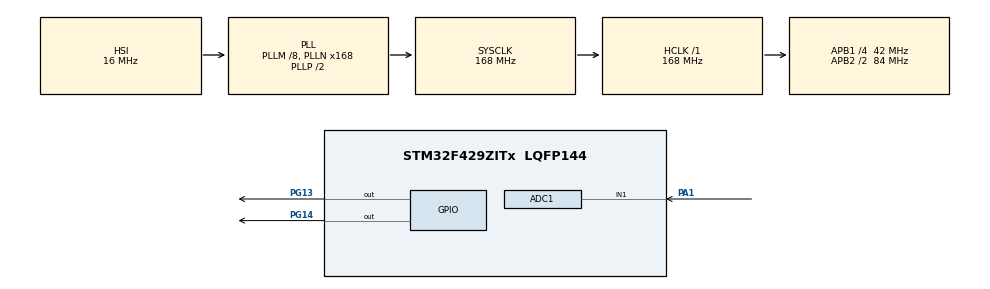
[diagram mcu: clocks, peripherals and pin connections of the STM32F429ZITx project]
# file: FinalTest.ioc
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ADC1.Channel-6\#ChannelRegularConversion=ADC_CHANNEL_1
ADC1.ClockPrescaler=ADC_CLOCK_SYNC_PCLK_DIV6
ADC1.ContinuousConvMode=ENABLE
ADC1.DMAContinuousRequests=ENABLE
ADC1.NbrOfConversion=1
ADC1.NbrOfConversionFlag=1
ADC1.Rank-6\#ChannelRegularConversion=1
ADC1.Resolution=ADC_RESOLUTION_8B
ADC1.SamplingTime-6\#ChannelRegularConversion=ADC_SAMPLETIME_112CYCLES
ADC1.master=1
Dma.ADC1.0.Direction=DMA_PERIPH_TO_MEMORY
Dma.ADC1.0.FIFOMode=DMA_FIFOMODE_DISABLE
Dma.ADC1.0.Instance=DMA2_Stream0
Dma.ADC1.0.MemDataAlignment=DMA_MDATAALIGN_WORD
Dma.ADC1.0.MemInc=DMA_MINC_ENABLE
Dma.ADC1.0.Mode=DMA_CIRCULAR
Dma.ADC1.0.PeriphDataAlignment=DMA_PDATAALIGN_WORD
Dma.ADC1.0.PeriphInc=DMA_PINC_DISABLE
Dma.ADC1.0.Priority=DMA_PRIORITY_HIGH
Dma.Request0=ADC1
Mcu.Family=STM32F4
Mcu.Name=STM32F429ZITx
Mcu.Package=LQFP144
NVIC.DMA2_Stream0_IRQn=true\:0\:0\:false\:false\:true\:false
NVIC.PriorityGroup=NVIC_PRIORITYGROUP_4
PA1.Signal=ADCx_IN1
PG13.Signal=GPIO_Output
PG14.Signal=GPIO_Output
PH0/OSC_IN.Mode=HSE-External-Oscillator
PH0/OSC_IN.Signal=RCC_OSC_IN
PH1/OSC_OUT.Mode=HSE-External-Oscillator
PH1/OSC_OUT.Signal=RCC_OSC_OUT
ProjectManager.HeapSize=0x200
ProjectManager.StackSize=0x400
ProjectManager.TargetToolchain=SW4STM32
RCC.48MHZClocksFreq_Value=112000000
RCC.AHBFreq_Value=168000000
RCC.APB1CLKDivider=RCC_HCLK_DIV4
RCC.APB1Freq_Value=42000000
RCC.APB1TimFreq_Value=84000000
RCC.APB2CLKDivider=RCC_HCLK_DIV2
RCC.APB2Freq_Value=84000000
RCC.APB2TimFreq_Value=168000000
RCC.CortexFreq_Value=168000000
RCC.HCLKFreq_Value=168000000
RCC.HSE_VALUE=8000000
RCC.HSI_VALUE=16000000
RCC.LSE_VALUE=32768
RCC.PLLM=8
RCC.PLLN=168
RCC.PLLQ=3
RCC.PLLSAIN=50
RCC.SYSCLKFreq_VALUE=168000000
RCC.SYSCLKSource=RCC_SYSCLKSOURCE_PLLCLK
RCC.VCOOutputFreq_Value=336000000
SH.ADCx_IN1.0=ADC1_IN1,IN1
board=32F429IDISCOVERY

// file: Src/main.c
/* USER CODE BEGIN Header */
/**
  ******************************************************************************
  * @file           : main.c
  * @brief          : Main program body
  ******************************************************************************
  ** This notice applies to any and all portions of this file
  * that are not between comment pairs USER CODE BEGIN and
  * USER CODE END. Other portions of this file, whether
  * inserted by the user or by software development tools
  * are owned by their respective copyright owners.
  *
  * COPYRIGHT(c) 2019 STMicroelectronics
  *
  * Redistribution and use in source and binary forms, with or without modification,
  * are permitted provided that the following conditions are met:
  *   1. Redistributions of source code must retain the above copyright notice,
  *      this list of conditions and the following disclaimer.
  *   2. Redistributions in binary form must reproduce the above copyright notice,
  *      this list of conditions and the following disclaimer in the documentation
  *      and/or other materials provided with the distribution.
  *   3. Neither the name of STMicroelectronics nor the names of its contributors
  *      may be used to endorse or promote products derived from this software
  *      without specific prior written permission.
  *
  * THIS SOFTWARE IS PROVIDED BY THE COPYRIGHT HOLDERS AND CONTRIBUTORS "AS IS"
  * AND ANY EXPRESS OR IMPLIED WARRANTIES, INCLUDING, BUT NOT LIMITED TO, THE
  * IMPLIED WARRANTIES OF MERCHANTABILITY AND FITNESS FOR A PARTICULAR PURPOSE ARE
  * DISCLAIMED. IN NO EVENT SHALL THE COPYRIGHT HOLDER OR CONTRIBUTORS BE LIABLE
  * FOR ANY DIRECT, INDIRECT, INCIDENTAL, SPECIAL, EXEMPLARY, OR CONSEQUENTIAL
  * DAMAGES (INCLUDING, BUT NOT LIMITED TO, PROCUREMENT OF SUBSTITUTE GOODS OR
  * SERVICES; LOSS OF USE, DATA, OR PROFITS; OR BUSINESS INTERRUPTION) HOWEVER
  * CAUSED AND ON ANY THEORY OF LIABILITY, WHETHER IN CONTRACT, STRICT LIABILITY,
  * OR TORT (INCLUDING NEGLIGENCE OR OTHERWISE) ARISING IN ANY WAY OUT OF THE USE
  * OF THIS SOFTWARE, EVEN IF ADVISED OF THE POSSIBILITY OF SUCH DAMAGE.
  *
  ******************************************************************************
  */
/* USER CODE END Header */

#include "main.h"

/* USER CODE BEGIN Includes */
#include "complex.h"
#include "math.h"
/* USER CODE END Includes */

ADC_HandleTypeDef hadc1;
DMA_HandleTypeDef hdma_adc1;

/* USER CODE BEGIN PV */
enum{ size = 8};
size_t N =8;
uint32_t buffer[size];
double complex twiddle[128];
double complex in[size] =  {0.3535,
							0.3535,
							0.6464,
							1.0607,
							0.3535,
							-1.0607,
							-1.3535,
							-0.3535};
double complex out[size];
int count1;
int count2;
int count3;
uint32_t g_ADCValue;
int g_MeasurementNumber;
/* USER CODE END PV */

void SystemClock_Config(void);
static void MX_GPIO_Init(void);
static void MX_DMA_Init(void);
static void MX_ADC1_Init(void);
/* USER CODE BEGIN PFP */

void Bit_reversal(double complex *in, size_t N);
void Cooley_tukey_FFT(double complex *in, double complex *out, double complex *W, size_t N);
void twiddle_maker(double complex *twiddle_factors,uint32_t fft_size);
void CopyArray(double complex *in, double complex *out, size_t N);
/* USER CODE END PFP */

/* USER CODE BEGIN 0 */

void CopyArray(double complex *in, double complex *out, size_t N)
{
	for (int i=0;i<N;i++)
	{
		out[i]=in[i];
	}
}
void Cooley_tukey_FFT(double complex *in, double complex *out, double complex *W, size_t N)
{
	Bit_reversal(in,N);
	int n=N;
	int twiddle_jump;
	int indic;
	for(int i=0; i<log2(n);++i)
	{
	  int Half_DFT_Size = pow(2,i);
	  int counter =0;
	  twiddle_jump=pow(2,n-i-1)/2;
	  for(int m=0;m<n;++m)
	  {
		if(counter==0)
		{
			indic=0;
		}
		else
		{
			indic=(counter*twiddle_jump);
			if (indic == 128)
				indic--;
		}
		if(counter>=Half_DFT_Size)
			out[m] = in[m-Half_DFT_Size] + (W[indic]*in[m]);
		else
			out[m] = in[m] + (W[indic]*in[m+Half_DFT_Size]);
		counter++;
		if(counter == (Half_DFT_Size*2))
			counter = 0;
	   }
		double complex *temp = in;
		in = out;
		out = temp;
	}
	out = in;
}

void twiddle_maker(double complex *twiddle_factors, uint32_t fft_size)
{
	uint32_t count;
	for(count=0;count<fft_size;count++)
	{
		twiddle_factors[count]=cexp(-1*I*M_PI*2*count/fft_size);
	}
}

void Bit_reversal(double complex *in, size_t N)
{
	int m = log2(N); //Number of bits
	for (int index=0; index<N/2;++index) //Up to half the array because pair values are swapped
	{
		int curr_addr = index;
		int New_addr = 0;
		int bits=0;
		while(curr_addr!=0)
		{
			//Calculating the mod of the index converts the number to binary but by instead counting down from the index of
			//the most significant bit and multiplying that with the remainder we obtain the equiavlent base-10 number reversed.
			int Remainder = (int)fmod(curr_addr,2); //current number mod2
			New_addr += Remainder*pow(2,m-1-bits); //multiplying remainder with most significant bit first
			curr_addr = floor(curr_addr/2); //dividing the current number by 2 as for normal binary conversion
			bits++;
		}
		/*
		for(int bits=0; bits<m;++bits)
		{
			//Calculating the mod of the index converts the number to binary but by instead counting down from the index of
			//the most significant bit and multiplying that with the remainder we obtain the equiavlent base-10 number reversed.
			int Remainder = (int)fmod(curr_addr,2); //current number mod2
			New_addr += Remainder*pow(2,m-1-bits); //multiplying remainder with most significant bit first
			curr_addr = floor(curr_addr/2); //dividing the current number by 2 as for normal binary conversion
		}
		*/
		//Swapping the values
		double complex temp = in[index];
		in[index] = in[New_addr];
		in[New_addr] = temp;
	}
	//fprintf("Length: %f", cpu_time_used);
	/*
	for (int i = 0; i < N; ++i)
	{
		int n = i;
		int a = i;
		int count = 0;
		count = (int)log2((double)N) - 1;

		n >>= 1;
		while (n > 0) {
			a = (a << 1) | (n & 1);
			count--;
			n >>= 1;
		}
		n = (a << count) & ((1 << (int)log2((double)N)) - 1);
		a=5;
		//if (n > i) {
		//	double complex tmp = X[i];
		//	X[i] = X[n];
		//	X[n] = tmp;
		//}
	}
	*/
}

void HAL_ADC_ConvCpltCallback(ADC_HandleTypeDef* hadc1)
{
	HAL_GPIO_TogglePin(GPIOG,GPIO_PIN_13);
	double g_ADCValue = HAL_ADC_GetValue(&hadc1);
	count1++;
}

void HAL_ADC_ConvHalfCpltCallback(ADC_HandleTypeDef* hadc1)
{
	HAL_GPIO_TogglePin(GPIOG,GPIO_PIN_13);
	double g_ADCValue = HAL_ADC_GetValue(&hadc1);

	count2++;
}

void ADC_DMAHalfConvCplt(DMA_HandleTypeDef* hdma_adc1)
{
	HAL_GPIO_TogglePin(GPIOG,GPIO_PIN_13);
	double g_ADCValue = HAL_ADC_GetValue(&hadc1);
	count3++;
}
/* USER CODE END 0 */

int main(void)
{

  /* MCU Configuration--------------------------------------------------------*/

  /* Reset of all peripherals, Initializes the Flash interface and the Systick. */
  HAL_Init();

  /* Configure the system clock */
  SystemClock_Config();

  /* Initialize all configured peripherals */
  MX_GPIO_Init();
  MX_DMA_Init();
  MX_ADC1_Init();
  /* USER CODE BEGIN 2 */
  //HAL_ADC_Start(&hadc1);
  HAL_ADC_Start_DMA(&hadc1,buffer,size);
  /* USER CODE END 2 */
  twiddle_maker(twiddle,128);
  CopyArray(in,out,N);
  Cooley_tukey_FFT(in,out,twiddle,N);
  /* Infinite loop */
  while (1)
  {

  }
}

void SystemClock_Config(void)
{
  RCC_OscInitTypeDef RCC_OscInitStruct = {0};
  RCC_ClkInitTypeDef RCC_ClkInitStruct = {0};

  /**Configure the main internal regulator output voltage
  */
  __HAL_RCC_PWR_CLK_ENABLE();
  __HAL_PWR_VOLTAGESCALING_CONFIG(PWR_REGULATOR_VOLTAGE_SCALE1);
  /**Initializes the CPU, AHB and APB busses clocks
  */
  RCC_OscInitStruct.OscillatorType = RCC_OSCILLATORTYPE_HSI;
  RCC_OscInitStruct.HSIState = RCC_HSI_ON;
  RCC_OscInitStruct.HSICalibrationValue = RCC_HSICALIBRATION_DEFAULT;
  RCC_OscInitStruct.PLL.PLLState = RCC_PLL_ON;
  RCC_OscInitStruct.PLL.PLLSource = RCC_PLLSOURCE_HSI;
  RCC_OscInitStruct.PLL.PLLM = 8;
  RCC_OscInitStruct.PLL.PLLN = 168;
  RCC_OscInitStruct.PLL.PLLP = RCC_PLLP_DIV2;
  RCC_OscInitStruct.PLL.PLLQ = 3;
  if (HAL_RCC_OscConfig(&RCC_OscInitStruct) != HAL_OK)
  {
    Error_Handler();
  }
  /**Initializes the CPU, AHB and APB busses clocks
  */
  RCC_ClkInitStruct.ClockType = RCC_CLOCKTYPE_HCLK|RCC_CLOCKTYPE_SYSCLK
                              |RCC_CLOCKTYPE_PCLK1|RCC_CLOCKTYPE_PCLK2;
  RCC_ClkInitStruct.SYSCLKSource = RCC_SYSCLKSOURCE_PLLCLK;
  RCC_ClkInitStruct.AHBCLKDivider = RCC_SYSCLK_DIV1;
  RCC_ClkInitStruct.APB1CLKDivider = RCC_HCLK_DIV4;
  RCC_ClkInitStruct.APB2CLKDivider = RCC_HCLK_DIV2;

  if (HAL_RCC_ClockConfig(&RCC_ClkInitStruct, FLASH_LATENCY_5) != HAL_OK)
  {
    Error_Handler();
  }
}

static void MX_ADC1_Init(void)
{

  ADC_ChannelConfTypeDef sConfig = {0};

  /**Configure the global features of the ADC (Clock, Resolution, Data Alignment and number of conversion)
  */
  hadc1.Instance = ADC1;
  hadc1.Init.ClockPrescaler = ADC_CLOCK_SYNC_PCLK_DIV6;
  hadc1.Init.Resolution = ADC_RESOLUTION_8B;
  hadc1.Init.ScanConvMode = DISABLE;
  hadc1.Init.ContinuousConvMode = ENABLE;
  hadc1.Init.DiscontinuousConvMode = DISABLE;
  hadc1.Init.ExternalTrigConvEdge = ADC_EXTERNALTRIGCONVEDGE_NONE;
  hadc1.Init.ExternalTrigConv = ADC_SOFTWARE_START;
  hadc1.Init.DataAlign = ADC_DATAALIGN_RIGHT;
  hadc1.Init.NbrOfConversion = 1;
  hadc1.Init.DMAContinuousRequests = ENABLE;
  hadc1.Init.EOCSelection = ADC_EOC_SINGLE_CONV;
  if (HAL_ADC_Init(&hadc1) != HAL_OK)
  {
    Error_Handler();
  }
  /**Configure for the selected ADC regular channel its corresponding rank in the sequencer and its sample time.
  */
  sConfig.Channel = ADC_CHANNEL_1;
  sConfig.Rank = 1;
  sConfig.SamplingTime = ADC_SAMPLETIME_112CYCLES;
  if (HAL_ADC_ConfigChannel(&hadc1, &sConfig) != HAL_OK)
  {
    Error_Handler();
  }

}

static void MX_DMA_Init(void)
{
  /* DMA controller clock enable */
  __HAL_RCC_DMA2_CLK_ENABLE();

  /* DMA interrupt init */
  /* DMA2_Stream0_IRQn interrupt configuration */

  HAL_NVIC_SetPriority(DMA2_Stream0_IRQn, 0, 0);
  HAL_NVIC_EnableIRQ(DMA2_Stream0_IRQn);

}

static void MX_GPIO_Init(void)
{
  GPIO_InitTypeDef GPIO_InitStruct = {0};
  GPIO_InitTypeDef ADC_GPIO_InitStruct = {0};

  /* GPIO Ports Clock Enable */
  __HAL_RCC_GPIOH_CLK_ENABLE();
  __HAL_RCC_GPIOA_CLK_ENABLE();
  __HAL_RCC_GPIOG_CLK_ENABLE();

  /*Configure GPIO pin Output Level */
  HAL_GPIO_WritePin(GPIOG, GPIO_PIN_13|GPIO_PIN_14, GPIO_PIN_RESET);

  /*Configure GPIO pins : PG13 PG14 */
  GPIO_InitStruct.Pin = GPIO_PIN_13|GPIO_PIN_14;
  GPIO_InitStruct.Mode = GPIO_MODE_OUTPUT_PP;
  GPIO_InitStruct.Pull = GPIO_NOPULL;
  GPIO_InitStruct.Speed = GPIO_SPEED_FREQ_LOW;
  HAL_GPIO_Init(GPIOG, &GPIO_InitStruct);
}

void Error_Handler(void)
{
  /* USER CODE BEGIN Error_Handler_Debug */
  /* User can add his own implementation to report the HAL error return state */

	/*

	 hdma_adc1.Instance = DMA2_Stream4;

  hdma_adc1.Init.Channel  = DMA_CHANNEL_0;
  hdma_adc1.Init.Direction = DMA_PERIPH_TO_MEMORY;
  hdma_adc1.Init.PeriphInc = DMA_PINC_DISABLE;
  hdma_adc1.Init.MemInc = DMA_MINC_ENABLE;
  hdma_adc1.Init.PeriphDataAlignment = DMA_PDATAALIGN_WORD;
  hdma_adc1.Init.MemDataAlignment = DMA_MDATAALIGN_WORD;
  hdma_adc1.Init.Mode = DMA_CIRCULAR;
  hdma_adc1.Init.Priority = DMA_PRIORITY_HIGH;
  hdma_adc1.Init.FIFOMode = DMA_FIFOMODE_DISABLE;
  hdma_adc1.Init.FIFOThreshold = DMA_FIFO_THRESHOLD_HALFFULL;
  hdma_adc1.Init.MemBurst = DMA_MBURST_SINGLE;
  hdma_adc1.Init.PeriphBurst = DMA_PBURST_SINGLE;

  HAL_DMA_Init(&hdma_adc1);

  __HAL_LINKDMA(&hadc1, DMA_Handle, hdma_adc1);

  HAL_NVIC_SetPriority(DMA2_Stream4_IRQn, 0, 0);
  HAL_NVIC_EnableIRQ(DMA2_Stream4_IRQn);
	 */
  /* USER CODE END Error_Handler_Debug */
}

/************************ (C) COPYRIGHT STMicroelectronics *****END OF FILE****/
